# ATSAME70N21B register map
Vendor: Microchip Technology; Series: SAME70; File version: 0
CPU: CM7 r1p1, little endian, MPU, FPU, 3 interrupt priority bits
Registers are 32-bit, read-write, reset 0x0 unless marked. A register's access mark holds for its fields unless they carry their own. Offsets are from the block's base; [hi:lo] are bit positions; lines under a group give offsets from that group; {n}, {i} and the like mark numbered series; 'fields as' and 'values as' point back to an identical list.

## TC0 — Timer Counter
Base 0x4000C000; register names take the prefix TC_
Same registers: TC1 0x40010000, TC2 0x40014000, TC3 0x40054000
{0x0+0x40*i} TC_CHANNEL[{i}] (i=0..2) group — Channel Control Register (channel = 0)
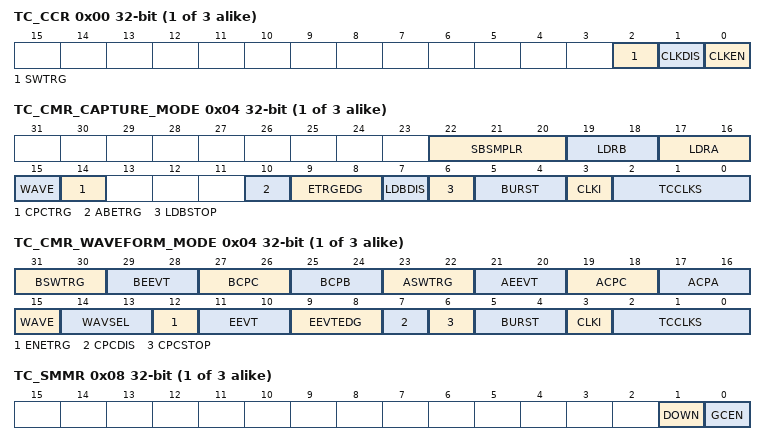
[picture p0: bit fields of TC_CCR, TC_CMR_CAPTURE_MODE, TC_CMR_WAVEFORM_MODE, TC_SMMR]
  0x00 TC_CCR wo — Channel Control Register (channel = 0)
    [2] SWTRG — Software Trigger Command
    [1] CLKDIS — Counter Clock Disable Command
    [0] CLKEN — Counter Clock Enable Command
  0x04 TC_CMR_CAPTURE_MODE — Channel Mode Register (channel = 0)
    [22:20] SBSMPLR — Loading Edge Subsampling Ratio
      0=ONE (Load a Capture Register each selected edge); 1=HALF (Load a Capture Register every 2 selected edges); 2=FOURTH (Load a Capture Register every 4 selected edges); 3=EIGHTH (Load a Capture Register every 8 selected edges); 4=SIXTEENTH (Load a Capture Register every 16 selected edges)
    [19:18] LDRB — RB Loading Edge Selection
      0=NONE; 1=RISING (Rising edge of TIOAx); 2=FALLING (Falling edge of TIOAx); 3=EDGE (Each edge of TIOAx)
    [17:16] LDRA — RA Loading Edge Selection
      values as LDRB
    [15] WAVE — Waveform Mode
    [14] CPCTRG — RC Compare Trigger Enable
    [10] ABETRG — TIOAx or TIOBx External Trigger Selection
    [9:8] ETRGEDG — External Trigger Edge Selection
      0=NONE (The clock is not gated by an external signal.); 1=RISING (Rising edge); 2=FALLING (Falling edge); 3=EDGE (Each edge)
    [7] LDBDIS — Counter Clock Disable with RB Loading
    [6] LDBSTOP — Counter Clock Stopped with RB Loading
    [5:4] BURST — Burst Signal Selection
      0=NONE (The clock is not gated by an external signal.); 1=XC0 (XC0 is ANDed with the selected clock.); 2=XC1 (XC1 is ANDed with the selected clock.); 3=XC2 (XC2 is ANDed with the selected clock.)
    [3] CLKI — Clock Invert
    [2:0] TCCLKS — Clock Selection
      0=TIMER_CLOCK1 (Clock selected: internal PCK6 clock signal (from PMC)); 1=TIMER_CLOCK2 (Clock selected: internal MCK/8 clock signal (from PMC)); 2=TIMER_CLOCK3 (Clock selected: internal MCK/32 clock signal (from PMC)); 3=TIMER_CLOCK4 (Clock selected: internal MCK/128 clock signal (from PMC)); 4=TIMER_CLOCK5 (Clock selected: internal SLCK clock signal (from PMC)); 5=XC0 (Clock selected: XC0); 6=XC1 (Clock selected: XC1); 7=XC2 (Clock selected: XC2)
  0x04 TC_CMR_WAVEFORM_MODE (alternate view of TC_CMR_CAPTURE_MODE) — Channel Mode Register (channel = 0)
    [31:30] BSWTRG — Software Trigger Effect on TIOBx
      0=NONE; 1=SET; 2=CLEAR; 3=TOGGLE
    [29:28] BEEVT — External Event Effect on TIOBx
      0=NONE; 1=SET; 2=CLEAR; 3=TOGGLE
    [27:26] BCPC — RC Compare Effect on TIOBx
      0=NONE; 1=SET; 2=CLEAR; 3=TOGGLE
    [25:24] BCPB — RB Compare Effect on TIOBx
      0=NONE; 1=SET; 2=CLEAR; 3=TOGGLE
    [23:22] ASWTRG — Software Trigger Effect on TIOAx
      0=NONE; 1=SET; 2=CLEAR; 3=TOGGLE
    [21:20] AEEVT — External Event Effect on TIOAx
      0=NONE; 1=SET; 2=CLEAR; 3=TOGGLE
    [19:18] ACPC — RC Compare Effect on TIOAx
      0=NONE; 1=SET; 2=CLEAR; 3=TOGGLE
    [17:16] ACPA — RA Compare Effect on TIOAx
      0=NONE; 1=SET; 2=CLEAR; 3=TOGGLE
    [15] WAVE — Waveform Mode
    [14:13] WAVSEL — Waveform Selection
      0=UP (UP mode without automatic trigger on RC Compare); 1=UPDOWN (UPDOWN mode without automatic trigger on RC Compare); 2=UP_RC (UP mode with automatic trigger on RC Compare); 3=UPDOWN_RC (UPDOWN mode with automatic trigger on RC Compare)
    [12] ENETRG — External Event Trigger Enable
    [11:10] EEVT — External Event Selection
      0=TIOB; 1=XC0; 2=XC1; 3=XC2
    [9:8] EEVTEDG — External Event Edge Selection
      0=NONE; 1=RISING (Rising edge); 2=FALLING (Falling edge); 3=EDGE (Each edges)
    [7] CPCDIS — Counter Clock Disable with RC Loading
    [6] CPCSTOP — Counter Clock Stopped with RC Compare
    [5:4] BURST — Burst Signal Selection
      values as TC_CHANNEL[0].TC_CMR_CAPTURE_MODE.BURST
    [3] CLKI — Clock Invert
    [2:0] TCCLKS — Clock Selection
      values as TC_CHANNEL[0].TC_CMR_CAPTURE_MODE.TCCLKS
  0x08 TC_SMMR — Stepper Motor Mode Register (channel = 0)
    [1] DOWN — Down Count
    [0] GCEN — Gray Count Enable
  0x0C TC_RAB ro — Register AB (channel = 0)
    [31:0] RAB — Register A or Register B
  0x10 TC_CV ro — Counter Value (channel = 0)
    [31:0] CV — Counter Value
  0x14 TC_RA — Register A (channel = 0)
    [31:0] RA — Register A
  0x18 TC_RB — Register B (channel = 0)
    [31:0] RB — Register B
  0x1C TC_RC — Register C (channel = 0)
    [31:0] RC — Register C
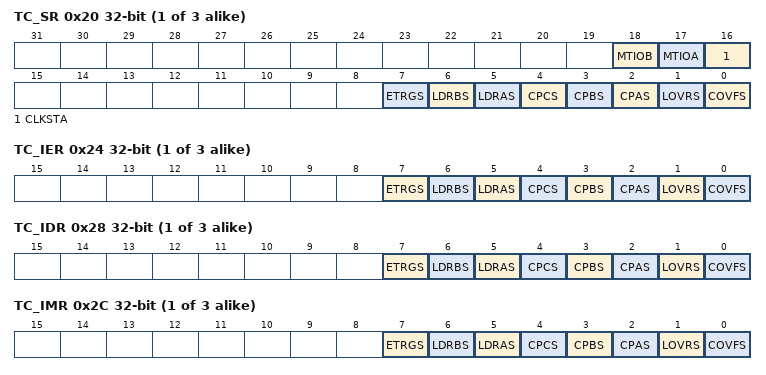
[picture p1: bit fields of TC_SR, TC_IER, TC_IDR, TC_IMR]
  0x20 TC_SR ro — Status Register (channel = 0)
    [18] MTIOB — TIOBx Mirror
    [17] MTIOA — TIOAx Mirror
    [16] CLKSTA — Clock Enabling Status
    [7] ETRGS — External Trigger Status (cleared on read)
    [6] LDRBS — RB Loading Status (cleared on read)
    [5] LDRAS — RA Loading Status (cleared on read)
    [4] CPCS — RC Compare Status (cleared on read)
    [3] CPBS — RB Compare Status (cleared on read)
    [2] CPAS — RA Compare Status (cleared on read)
    [1] LOVRS — Load Overrun Status (cleared on read)
    [0] COVFS — Counter Overflow Status (cleared on read)
  0x24 TC_IER wo — Interrupt Enable Register (channel = 0)
    [7] ETRGS — External Trigger
    [6] LDRBS — RB Loading
    [5] LDRAS — RA Loading
    [4] CPCS — RC Compare
    [3] CPBS — RB Compare
    [2] CPAS — RA Compare
    [1] LOVRS — Load Overrun
    [0] COVFS — Counter Overflow
  0x28 TC_IDR wo — Interrupt Disable Register (channel = 0)
    fields as TC_CHANNEL[0].TC_IER
  0x2C TC_IMR ro — Interrupt Mask Register (channel = 0)
    fields as TC_CHANNEL[0].TC_IER
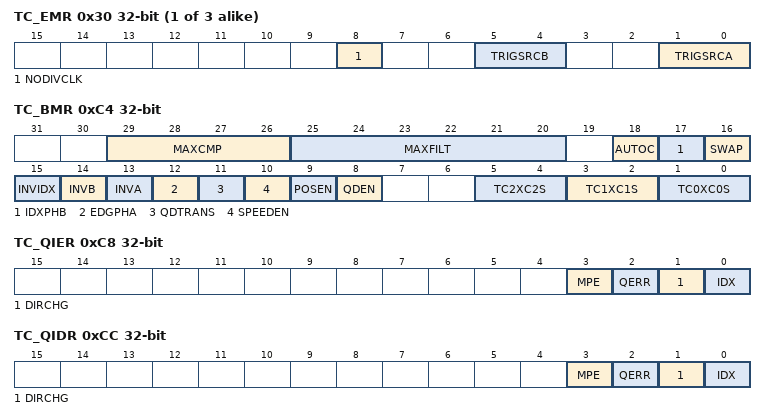
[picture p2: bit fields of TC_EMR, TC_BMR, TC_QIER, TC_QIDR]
  0x30 TC_EMR — Extended Mode Register (channel = 0)
    [8] NODIVCLK — No Divided Clock
    [5:4] TRIGSRCB — Trigger Source for Input B
      0=EXTERNAL_TIOBx (The trigger/capture input B is driven by external pin TIOBx); 1=PWMx (For TC0 to TC10: The trigger/capture input B is driven internally by the comparator output (see Figure 7-16) of the PWMx.For TC11: The trigger/capture input B is driven internally by the GTSUCOMP signal of the Ethernet MAC (GMAC).)
    [1:0] TRIGSRCA — Trigger Source for Input A
      0=EXTERNAL_TIOAx (The trigger/capture input A is driven by external pin TIOAx); 1=PWMx (The trigger/capture input A is driven internally by PWMx)
0xC0 TC_BCR wo — Block Control Register
  [0] SYNC — Synchro Command
0xC4 TC_BMR — Block Mode Register
  [29:26] MAXCMP — Maximum Consecutive Missing Pulses
  [25:20] MAXFILT — Maximum Filter
  [18] AUTOC — AutoCorrection of missing pulses
  [17] IDXPHB — Index Pin is PHB Pin
  [16] SWAP — Swap PHA and PHB
  [15] INVIDX — Inverted Index
  [14] INVB — Inverted PHB
  [13] INVA — Inverted PHA
  [12] EDGPHA — Edge on PHA Count Mode
  [11] QDTRANS — Quadrature Decoding Transparent
  [10] SPEEDEN — Speed Enabled
  [9] POSEN — Position Enabled
  [8] QDEN — Quadrature Decoder Enabled
  [5:4] TC2XC2S — External Clock Signal 2 Selection
    0=TCLK2 (Signal connected to XC2: TCLK2); 2=TIOA0 (Signal connected to XC2: TIOA0); 3=TIOA1 (Signal connected to XC2: TIOA1)
  [3:2] TC1XC1S — External Clock Signal 1 Selection
    0=TCLK1 (Signal connected to XC1: TCLK1); 2=TIOA0 (Signal connected to XC1: TIOA0); 3=TIOA2 (Signal connected to XC1: TIOA2)
  [1:0] TC0XC0S — External Clock Signal 0 Selection
    0=TCLK0 (Signal connected to XC0: TCLK0); 2=TIOA1 (Signal connected to XC0: TIOA1); 3=TIOA2 (Signal connected to XC0: TIOA2)
0xC8 TC_QIER wo — QDEC Interrupt Enable Register
  [3] MPE — Consecutive Missing Pulse Error
  [2] QERR — Quadrature Error
  [1] DIRCHG — Direction Change
  [0] IDX — Index
0xCC TC_QIDR wo — QDEC Interrupt Disable Register
  fields as TC_QIER
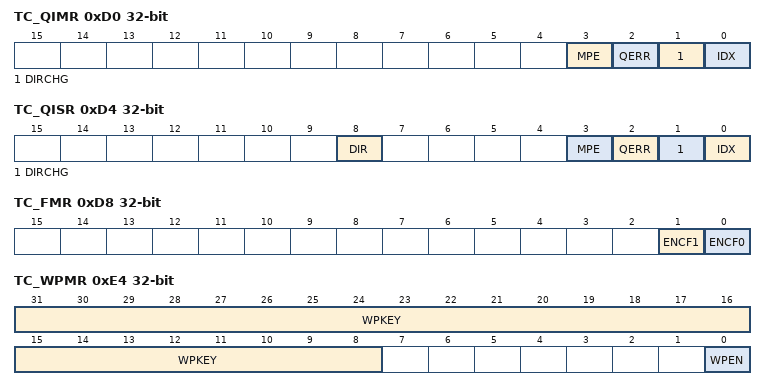
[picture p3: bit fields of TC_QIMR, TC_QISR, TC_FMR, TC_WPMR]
0xD0 TC_QIMR ro — QDEC Interrupt Mask Register
  fields as TC_QIER
0xD4 TC_QISR ro — QDEC Interrupt Status Register
  [8] DIR — Direction
  [3] MPE — Consecutive Missing Pulse Error
  [2] QERR — Quadrature Error
  [1] DIRCHG — Direction Change
  [0] IDX — Index
0xD8 TC_FMR — Fault Mode Register
  [1] ENCF1 — Enable Compare Fault Channel 1
  [0] ENCF0 — Enable Compare Fault Channel 0
0xE4 TC_WPMR — Write Protection Mode Register
  [31:8] WPKEY — Write Protection Key
    0x54494D=PASSWD (Writing any other value in this field aborts the write operation of the WPEN bit.Always reads as 0.)
  [0] WPEN — Write Protection Enable

## Notices in the file
Copyright (c) 2017 Microchip Technology Inc.
SPDX-License-Identifier: Apache-2.0
Licensed under the Apache License, Version 2.0 (the "License");
you may not use this file except in compliance with the License.
You may obtain a copy of the License at
http://www.apache.org/licenses/LICENSE-2.0
Unless required by applicable law or agreed to in writing, software
distributed under the License is distributed on an "AS IS" BASIS,
WITHOUT WARRANTIES OR CONDITIONS OF ANY KIND, either express or implied.
See the License for the specific language governing permissions and
limitations under the License.
